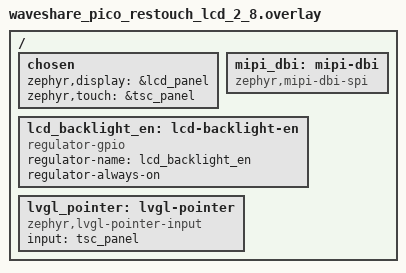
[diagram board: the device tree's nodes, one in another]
/*
 * SPDX-FileCopyrightText: Copyright (c) 2024-2026 TiaC Systems
 * SPDX-License-Identifier: Apache-2.0
 */

#include <zephyr/dt-bindings/input/input-event-codes.h>

/ {
	chosen {
		zephyr,display = &lcd_panel;
		zephyr,touch = &tsc_panel;
	};

	mipi_dbi: mipi-dbi {
		compatible = "zephyr,mipi-dbi-spi";
	};

	lcd_backlight_en: lcd-backlight-en {
		compatible = "regulator-gpio";
		regulator-name = "lcd_backlight_en";
		regulator-always-on;
	};

	lvgl_pointer: lvgl-pointer {
		compatible = "zephyr,lvgl-pointer-input";
		input = <&tsc_panel>;
	};
};
